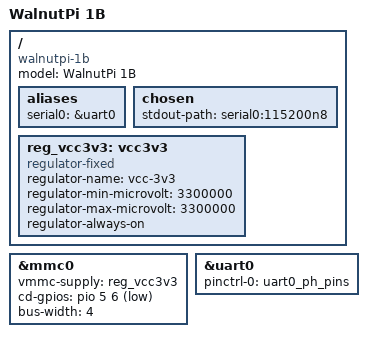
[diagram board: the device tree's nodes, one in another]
// SPDX-License-Identifier: (GPL-2.0+ OR MIT)
/*
 * Copyright (C) 2024 Arm Ltd.
 */

/dts-v1/;

#include "sun50i-h616.dtsi"

#include <dt-bindings/gpio/gpio.h>
#include <dt-bindings/interrupt-controller/arm-gic.h>
#include <dt-bindings/leds/common.h>

/ {
	model = "WalnutPi 1B";
	compatible = "walnutpi-1b", "allwinner,sun50i-h616";

	aliases {
		serial0 = &uart0;
	};

	chosen {
		stdout-path = "serial0:115200n8";
	};

	reg_vcc3v3: vcc3v3 {
		compatible = "regulator-fixed";
		regulator-name = "vcc-3v3";
		regulator-min-microvolt = <3300000>;
		regulator-max-microvolt = <3300000>;
		regulator-always-on;
	};
};

&mmc0 {
	vmmc-supply = <&reg_vcc3v3>;
	cd-gpios = <&pio 5 6 GPIO_ACTIVE_LOW>;	/* PF6 */
	bus-width = <4>;
	status = "okay";
};

&uart0 {
	pinctrl-names = "default";
	pinctrl-0 = <&uart0_ph_pins>;
	status = "okay";
};
